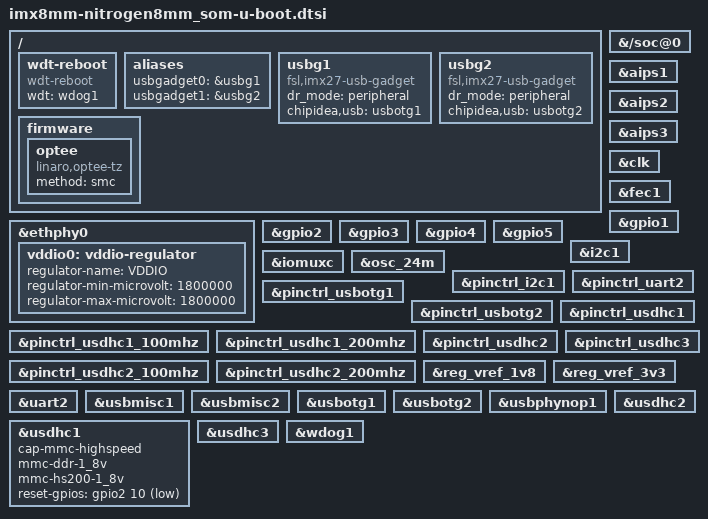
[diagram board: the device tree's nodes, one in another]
// SPDX-License-Identifier: GPL-2.0+
/*
 * Copyright 2019 NXP
 */
#include "imx8mm-nitrogen8mm_rev2-u-boot.dtsi"

/ {
	wdt-reboot {
		compatible = "wdt-reboot";
		wdt = <&wdog1>;
		bootph-pre-ram;
	};

	aliases {
		usbgadget0 = &usbg1;
		usbgadget1 = &usbg2;
	};

	usbg1: usbg1 {
	       compatible = "fsl,imx27-usb-gadget";
	       dr_mode = "peripheral";
	       chipidea,usb = <&usbotg1>;
	       status = "okay";
       };

	usbg2: usbg2 {
	       compatible = "fsl,imx27-usb-gadget";
	       dr_mode = "peripheral";
	       chipidea,usb = <&usbotg2>;
	       status = "okay";
       };

       firmware {
	       optee {
		       compatible = "linaro,optee-tz";
		       method = "smc";
	       };
       };
};

&{/soc@0} {
	bootph-pre-ram;
};

&aips1 {
	bootph-pre-ram;
};

&aips2 {
	bootph-pre-ram;
};

&aips3 {
	bootph-pre-ram;
};

&clk {
	bootph-pre-ram;
	/delete-property/ assigned-clocks;
	/delete-property/ assigned-clock-parents;
	/delete-property/ assigned-clock-rates;
};

&fec1 {
	// phy-reset-gpios = <&gpio3 15 GPIO_ACTIVE_LOW>;
	// phy-reset-duration = <15>;
	// phy-reset-post-delay = <100>;
};

&ethphy0 {
	vddio0: vddio-regulator {
		regulator-name = "VDDIO";
		regulator-min-microvolt = <1800000>;
		regulator-max-microvolt = <1800000>;
	};
};

&gpio1 {
	bootph-pre-ram;
};

&gpio2 {
	bootph-pre-ram;
};

&gpio3 {
	bootph-pre-ram;
};

&gpio4 {
	bootph-pre-ram;
};

&gpio5 {
	bootph-pre-ram;
};

&i2c1 {
	bootph-pre-ram;
};

&iomuxc {
	bootph-pre-ram;
};

&osc_24m {
	bootph-pre-ram;
	bootph-pre-ram;
};

&pinctrl_i2c1 {
	bootph-pre-ram;
};

&pinctrl_uart2 {
	bootph-pre-ram;
};

&pinctrl_usbotg1 {
	bootph-pre-ram;
};

&pinctrl_usbotg2 {
	bootph-pre-ram;
};

&pinctrl_usdhc1 {
	bootph-pre-ram;
};

&pinctrl_usdhc1_100mhz {
	bootph-pre-ram;
};

&pinctrl_usdhc1_200mhz {
	bootph-pre-ram;
};

&pinctrl_usdhc2 {
	bootph-pre-ram;
};

&pinctrl_usdhc2_100mhz {
	bootph-pre-ram;
};

&pinctrl_usdhc2_200mhz {
	bootph-pre-ram;
};

&pinctrl_usdhc3 {
	bootph-pre-ram;
};

&reg_vref_1v8 {
	bootph-pre-ram;
};

&reg_vref_3v3 {
	bootph-pre-ram;
};

&uart2 {
	bootph-pre-ram;
};

&usbmisc1 {
	bootph-pre-ram;
};

&usbmisc2 {
	bootph-pre-ram;
};

&usbotg1 {
	bootph-pre-ram;
};

&usbotg2 {
	bootph-pre-ram;
};

&usbphynop1 {
	bootph-pre-ram;
};

&usdhc1 {
	cap-mmc-highspeed;
	mmc-ddr-1_8v;
	mmc-hs200-1_8v;
	reset-gpios = <&gpio2 10 GPIO_ACTIVE_LOW>;
	bootph-pre-ram;
};

&usdhc2 {
	bootph-pre-ram;
};

&usdhc3 {
	bootph-pre-ram;
};

&wdog1 {
	bootph-pre-ram;
};
